# GD32H77x_78x register map
File version: 1.0
CPU: CM7 r1p2, little endian, MPU, FPU, 4 interrupt priority bits
Registers are 32-bit, read-write, reset 0x0 unless marked. A register's access mark holds for its fields unless they carry their own. Offsets are from the block's base; [hi:lo] are bit positions.

## ENET0_DMA — Ethernet: DMA controller operation
Base 0x40029000
Same registers: ENET1_DMA 0x4002B000
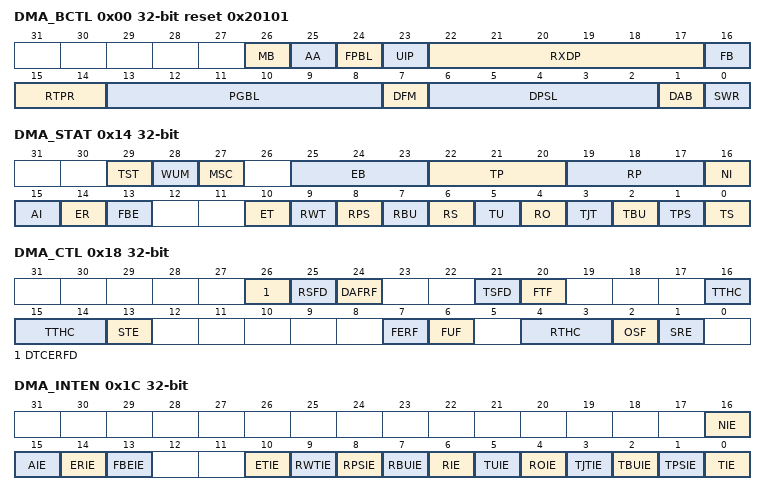
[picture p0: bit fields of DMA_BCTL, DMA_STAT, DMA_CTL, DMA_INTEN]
0x00 DMA_BCTL reset 0x20101 — Ethernet DMA bus control register
  [26] MB — Mixed burst
  [25] AA — Address-aligned
  [24] FPBL — Four times PGBL mode
  [23] UIP — Use independent PGBL
  [22:17] RXDP — Rx DMA PGBL
  [16] FB — Fixed burst
  [15:14] RTPR — RxDMA and TxDMA transfer priority ratio
  [13:8] PGBL — Programmable burst length
  [7] DFM — Descriptor format mode
  [6:2] DPSL — Descriptor skip length
  [1] DAB — DMA Arbitration
  [0] SWR — Software reset
0x04 DMA_TPEN — Ethernet DMA transmit poll enable register
  [31:0] TPE — Transmit poll enable
0x08 DMA_RPEN — Ethernet DMA receive poll enable register
  [31:0] RPE — Receive poll enable
0x0C DMA_RDTADDR — Ethernet DMA receive descriptor table address register
  [31:0] SRT — Start address of receive table
0x10 DMA_TDTADDR — Ethernet DMA transmit descriptor table address register
  [31:0] STT — Start address of transmit table
0x14 DMA_STAT access per field — Ethernet DMA status register
  [29] TST ro — Time stamp trigger status
  [28] WUM ro — WUM status
  [27] MSC ro — MSC status
  [25:23] EB ro — Error bits status
  [22:20] TP ro — Transmit process state
  [19:17] RP ro — Receive process state
  [16] NI rw — Normal interrupt summary
  [15] AI rw — Abnormal interrupt summary
  [14] ER rw — Early receive status
  [13] FBE rw — Fatal bus error status
  [10] ET rw — Early transmit status
  [9] RWT rw — Receive watchdog timeout status
  [8] RPS rw — Receive process stopped status
  [7] RBU rw — Receive buffer unavailable status
  [6] RS rw — Receive status
  [5] TU rw — Transmit underflow status
  [4] RO rw — Receive overflow status
  [3] TJT rw — Transmit jabber timeout status
  [2] TBU rw — Transmit buffer unavailable status
  [1] TPS rw — Transmit process stopped status
  [0] TS rw — Transmit status
0x18 DMA_CTL — Ethernet DMA control register
  [26] DTCERFD — Dropping of TCP/IP checksum error frames disable
  [25] RSFD — Receive Store-and-Forward
  [24] DAFRF — Disable flushing of received frames
  [21] TSFD — Transmit Store-and-Forward
  [20] FTF — Flush transmit FIFO
  [16:14] TTHC — Transmit threshold control
  [13] STE — Start/stop transmission enable
  [7] FERF — Forward error frames
  [6] FUF — Forward undersized good frames
  [4:3] RTHC — Receive threshold control
  [2] OSF — Operate on second frame
  [1] SRE — Start/stop receive enable
0x1C DMA_INTEN — Ethernet DMA interrupt enable register
  [16] NIE — Normal interrupt summary enable
  [15] AIE — Abnormal interrupt summary enable
  [14] ERIE — Early receive interrupt enable
  [13] FBEIE — Fatal bus error interrupt enable
  [10] ETIE — Early transmit interrupt enable
  [9] RWTIE — receive watchdog timeout interrupt enable
  [8] RPSIE — Receive process stopped interrupt enable
  [7] RBUIE — Receive buffer unavailable interrupt enable
  [6] RIE — Receive interrupt enable
  [5] TUIE — Transmit underflow interrupt enable
  [4] ROIE — Receive overflow interrupt enable
  [3] TJTIE — Transmit jabber timeout interrupt enable
  [2] TBUIE — Transmit buffer unavailable interrupt enable
  [1] TPSIE — Transmit process stopped interrupt enable
  [0] TIE — Transmit interrupt enable
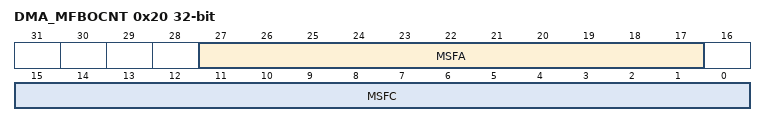
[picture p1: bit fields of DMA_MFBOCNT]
0x20 DMA_MFBOCNT ro — Ethernet DMA missed frame and buffer overflow counter register
  [27:17] MSFA — Missed frames by the application
  [15:0] MSFC — Missed frames by the controller
0x24 DMA_RSWDC — Ethernet DMA receive state watchdog counter register
  [7:0] WDCFRS — Watchdog counter for receive status (RS)
0x48 DMA_CTDADDR ro — DMA current transmit descriptor address register
  [31:0] TDAP — transmit descriptor address pointer
0x4C DMA_CRDADDR ro — Ethernet DMA current receive descriptor address register
  [31:0] RDAP — Receive descriptor address pointer
0x50 DMA_CTBADDR ro — Ethernet DMA current transmit buffer address register
  [31:0] TBAP — Transmit buffer address pointer
0x54 DMA_CRBADDR ro — Ethernet DMA current receive buffer address register
  [31:0] RBAP — receive buffer address pointer
